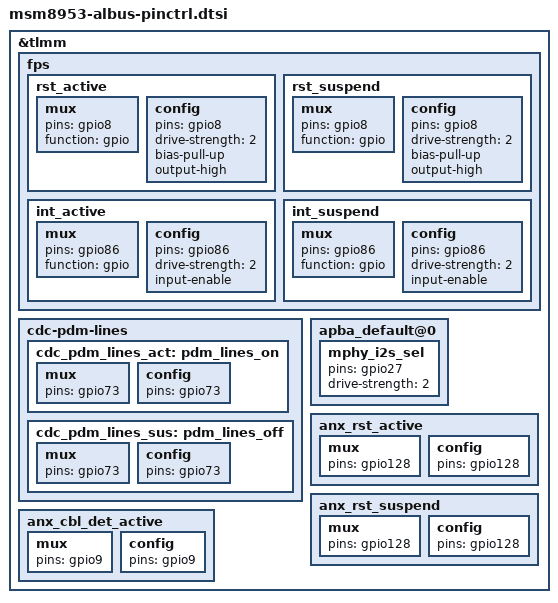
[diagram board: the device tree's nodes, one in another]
/* Copyright (c) 2016, Motorola Mobility Inc. All rights reserved.
 *
 * This program is free software; you can redistribute it and/or modify
 * it under the terms of the GNU General Public License version 2 and
 * only version 2 as published by the Free Software Foundation.
 *
 * This program is distributed in the hope that it will be useful,
 * but WITHOUT ANY WARRANTY; without even the implied warranty of
 * MERCHANTABILITY or FITNESS FOR A PARTICULAR PURPOSE.  See the
 * GNU General Public License for more details.
 */

&tlmm{
	/delete-node/ pmx_motosh_out;
	/delete-node/ pmx_motosh_in;
	/delete-node/ laser_active;
	/delete-node/ laser_suspend;

	fps: fps {
		rst_active: rst_active {
			/* RESET */
			mux {
				pins = "gpio8";
				function = "gpio";
			};

			config {
				pins = "gpio8";
				drive-strength = <2>; /* 2 MA */
				bias-pull-up; /* pull up */
				output-high;
			};
		};

		rst_suspend: rst_suspend{
			/* RESET */
			mux {
				pins = "gpio8";
				function = "gpio";
			};

			config {
				pins = "gpio8";
				drive-strength = <2>; /* 2 MA */
				bias-pull-up; /* pull up */
				output-high;
			};
		};

		int_active: int_active {
			/* INTERRUPT */
			mux {
				pins = "gpio86";
				function = "gpio";
			};

			config {
				pins = "gpio86";
				drive-strength = <2>; /* 2 MA */
				input-enable;
			};
		};

		int_suspend: int_suspend{
			/* INTERRUPT */
			mux {
				pins = "gpio86";
				function = "gpio";
			};

			config {
				pins = "gpio86";
				drive-strength = <2>; /* 2 MA */
				input-enable;
			};
		};
	};

	cdc-pdm-lines {
		cdc_pdm_lines_act: pdm_lines_on {
			mux {
				/delete-property/ pins;
				pins = "gpio73";
			};

			config {
				/delete-property/ pins;
				pins = "gpio73";
			};
		};

		cdc_pdm_lines_sus: pdm_lines_off {
			mux {
				/delete-property/ pins;
				pins = "gpio73";
			};

			config {
				/delete-property/ pins;
				pins = "gpio73";
			};
		};
	};

	apba_default@0 {
		mphy_i2s_sel {
			pins = "gpio27";
			drive-strength = <2>;
		};
	};

	anx_rst_active {
		mux {
			pins = "gpio128";
		};
		config {
			pins = "gpio128";
		};
	};
	anx_rst_suspend {
		mux {
			pins = "gpio128";
		};
		config {
			pins = "gpio128";
		};
	};
	anx_cbl_det_active {
		mux {
			pins = "gpio9";
		};
		config {
			pins = "gpio9";
		};
	};
};
